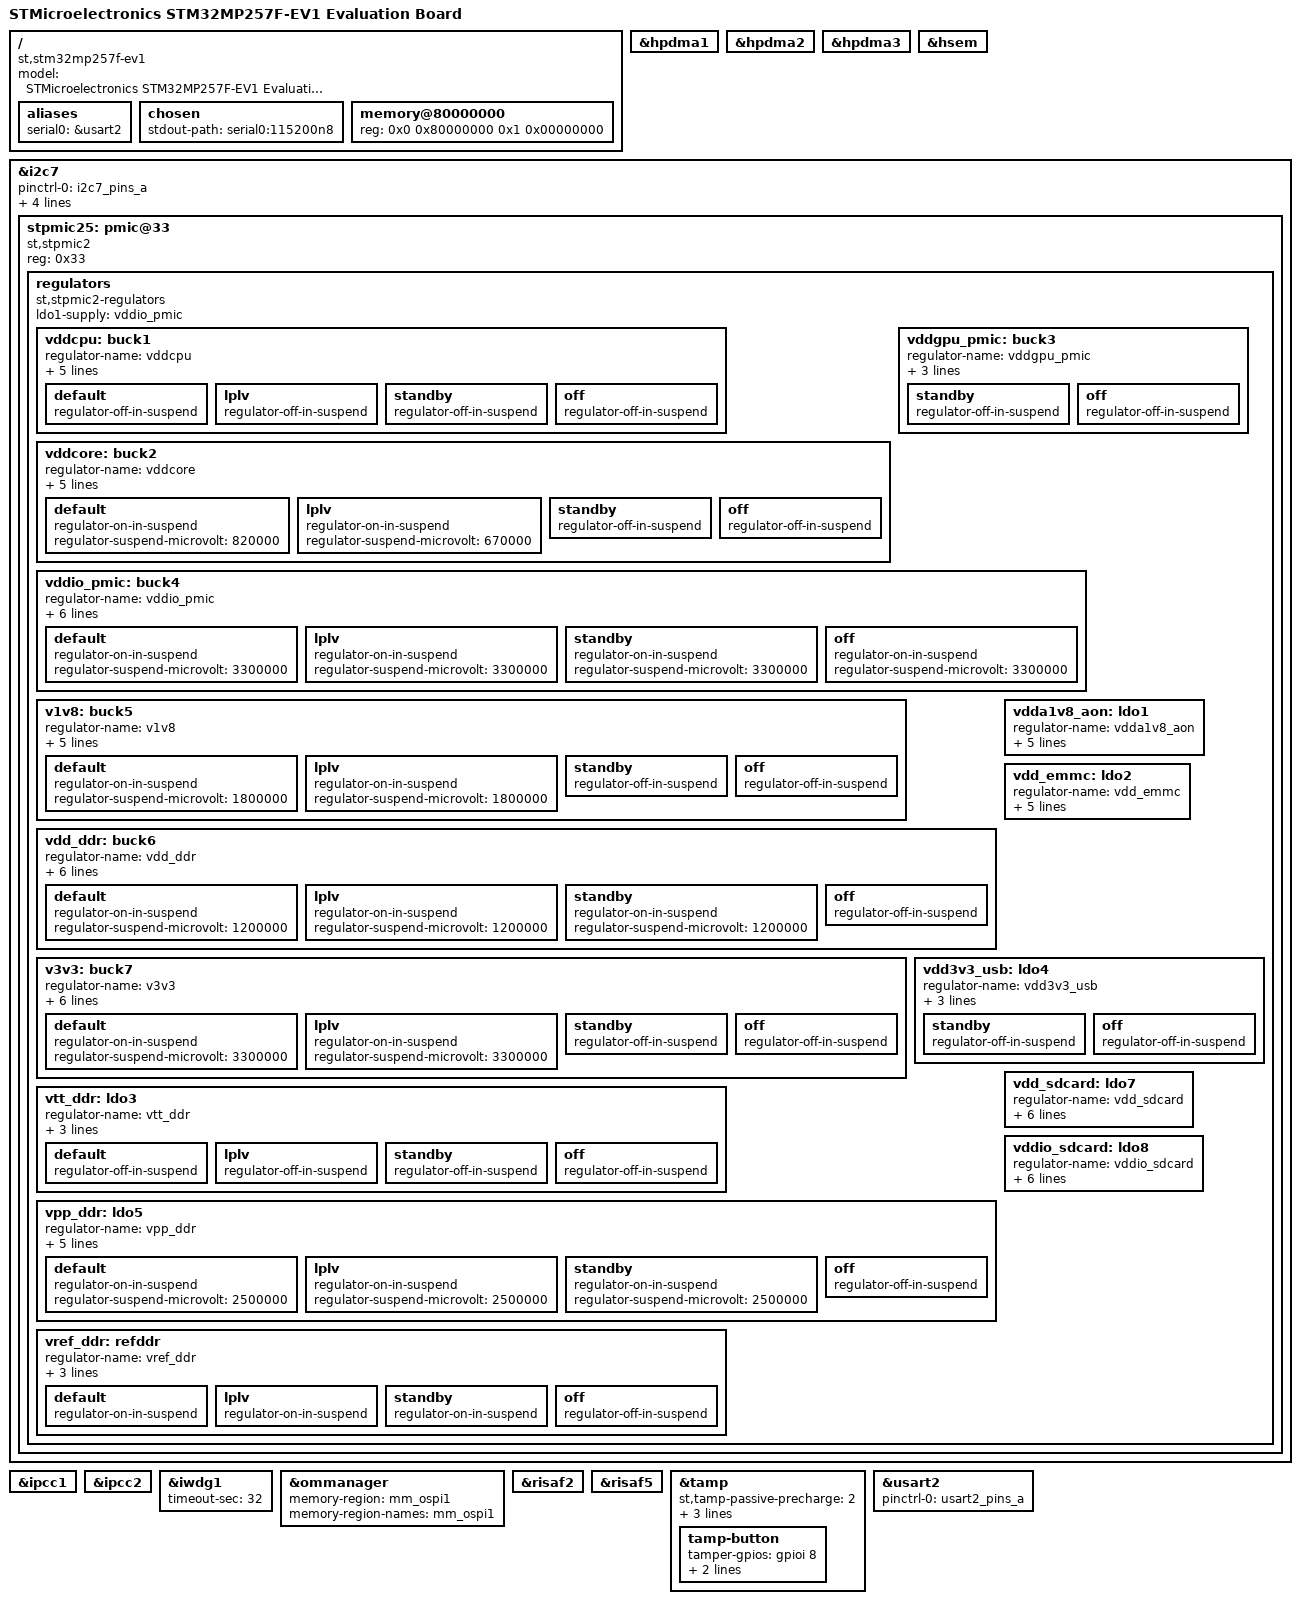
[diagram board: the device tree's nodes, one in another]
// SPDX-License-Identifier: (GPL-2.0-or-later OR BSD-3-Clause)
/*
 * Copyright (C) STMicroelectronics 2023 - All Rights Reserved
 * Author: Alexandre Torgue <alexandre.torgue@foss.st.com> for STMicroelectronics.
 */

/dts-v1/;
#include <dt-bindings/clock/stm32mp25-clksrc.h>
#include <dt-bindings/mfd/st,stpmic2.h>
#include <dt-bindings/tamper/st,stm32mp25-tamp.h>
#include "stm32mp257.dtsi"
#include "stm32mp257f-ev1-ca35tdcid-rcc.dtsi"
#include "stm32mp257f-ev1-ca35tdcid-resmem.dtsi"
#include "stm32mp257f-ev1-ca35tdcid-rif.dtsi"
#include "stm32mp25xf.dtsi"
#include "stm32mp25-pinctrl.dtsi"
#include "stm32mp25-st-scmi-cfg.dtsi"
#include "stm32mp25xxai-pinctrl.dtsi"

/ {
	model = "STMicroelectronics STM32MP257F-EV1 Evaluation Board";
	compatible = "st,stm32mp257f-ev1", "st,stm32mp257";

	aliases {
		serial0 = &usart2;
	};

	chosen {
		stdout-path = "serial0:115200n8";
	};

	memory@80000000 {
		device_type = "memory";
		reg = <0x0 0x80000000 0x1 0x00000000>;
	};
};

&hpdma1 {
	status = "okay";
};

&hpdma2 {
	status = "okay";
};

&hpdma3 {
	status = "okay";
};

&hsem {
	status = "okay";
};

&i2c7 {
	pinctrl-names = "default", "sleep";
	pinctrl-0 = <&i2c7_pins_a>;
	pinctrl-1 = <&i2c7_sleep_pins_a>;
	i2c-scl-rising-time-ns = <29>;
	i2c-scl-falling-time-ns = <7>;
	clock-frequency = <400000>;
	#address-cells = <1>;
	#size-cells = <0>;

	status = "okay";

	stpmic25: pmic@33 {
		compatible = "st,stpmic2";
		reg = <0x33>;

		status = "okay";

		regulators {
			compatible = "st,stpmic2-regulators";
			ldo1-supply = <&vddio_pmic>;

			vddcpu: buck1 {
				regulator-name = "vddcpu";
				regulator-min-microvolt = <800000>;
				regulator-max-microvolt = <910000>;
				regulator-always-on;
				st,pwrctrl-sel = <2>;
				st,pwrctrl-enable;

				default {
					regulator-off-in-suspend;
				};
				lplv {
					regulator-off-in-suspend;
				};
				standby {
					regulator-off-in-suspend;
				};
				off {
					regulator-off-in-suspend;
				};
			};
			vddcore: buck2 {
				regulator-name = "vddcore";
				regulator-min-microvolt = <820000>;
				regulator-max-microvolt = <820000>;
				regulator-always-on;
				st,pwrctrl-sel = <1>;
				st,pwrctrl-enable;

				default {
					regulator-on-in-suspend;
					regulator-suspend-microvolt = <820000>;
				};
				lplv {
					regulator-on-in-suspend;
					regulator-suspend-microvolt = <670000>;
				};
				standby {
					regulator-off-in-suspend;
				};
				off {
					regulator-off-in-suspend;
				};
			};
			vddgpu_pmic: buck3 {
				regulator-name = "vddgpu_pmic";
				regulator-min-microvolt = <800000>;
				regulator-max-microvolt = <900000>;
				regulator-over-current-protection;

				standby {
					regulator-off-in-suspend;
				};
				off {
					regulator-off-in-suspend;
				};
			};
			vddio_pmic: buck4 {
				regulator-name = "vddio_pmic";
				regulator-min-microvolt = <3300000>;
				regulator-max-microvolt = <3300000>;
				regulator-always-on;
				st,mask-reset;
				st,pwrctrl-sel = <1>;
				st,pwrctrl-enable;

				default {
					regulator-on-in-suspend;
					regulator-suspend-microvolt = <3300000>;
				};
				lplv {
					regulator-on-in-suspend;
					regulator-suspend-microvolt = <3300000>;
				};
				standby {
					regulator-on-in-suspend;
					regulator-suspend-microvolt = <3300000>;
				};
				off {
					/* ToDo: switch to LP */
					regulator-on-in-suspend;
					regulator-suspend-microvolt = <3300000>;
				};
			};
			v1v8: buck5 {
				regulator-name = "v1v8";
				regulator-min-microvolt = <1800000>;
				regulator-max-microvolt = <1800000>;
				regulator-always-on;
				st,pwrctrl-sel = <1>;
				st,pwrctrl-enable;

				default {
					regulator-on-in-suspend;
					regulator-suspend-microvolt = <1800000>;
				};
				lplv {
					regulator-on-in-suspend;
					regulator-suspend-microvolt = <1800000>;
				};
				standby {
					regulator-off-in-suspend;
				};
				off {
					regulator-off-in-suspend;
				};
			};
			vdd_ddr: buck6 {
				regulator-name = "vdd_ddr";
				regulator-min-microvolt = <1200000>;
				regulator-max-microvolt = <1200000>;
				regulator-always-on;
				regulator-pull-down;
				st,pwrctrl-sel = <1>;
				st,pwrctrl-enable;

				default {
					regulator-on-in-suspend;
					regulator-suspend-microvolt = <1200000>;
				};
				lplv {
					regulator-on-in-suspend;
					regulator-suspend-microvolt = <1200000>;
				};
				standby {
					regulator-on-in-suspend;
					regulator-suspend-microvolt = <1200000>;
				};
				off {
					regulator-off-in-suspend;
				};
			};
			v3v3: buck7 {
				regulator-name = "v3v3";
				regulator-min-microvolt = <3300000>;
				regulator-max-microvolt = <3300000>;
				regulator-always-on;
				regulator-over-current-protection;
				st,pwrctrl-sel = <1>;
				st,pwrctrl-enable;

				default {
					regulator-on-in-suspend;
					regulator-suspend-microvolt = <3300000>;
				};
				lplv {
					regulator-on-in-suspend;
					regulator-suspend-microvolt = <3300000>;
				};
				standby {
					regulator-off-in-suspend;
				};
				off {
					regulator-off-in-suspend;
				};
			};
			vdda1v8_aon: ldo1 {
				regulator-name = "vdda1v8_aon";
				regulator-min-microvolt = <1800000>;
				regulator-max-microvolt = <1800000>;
				regulator-always-on;
				st,alternate-input-source;
				st,mask-reset;
			};
			vdd_emmc: ldo2 {
				regulator-name = "vdd_emmc";
				regulator-min-microvolt = <3300000>;
				regulator-max-microvolt = <3300000>;
				regulator-over-current-protection;
				st,pwrctrl-sel = <3>;
				st,pwrctrl-reset;
			};
			vtt_ddr: ldo3 {
				regulator-name = "vtt_ddr";
				regulator-always-on;
				st,pwrctrl-sel = <1>;
				st,pwrctrl-enable;

				default {
					regulator-off-in-suspend;
				};
				lplv {
					regulator-off-in-suspend;
				};
				standby {
					regulator-off-in-suspend;
				};
				off {
					regulator-off-in-suspend;
				};
			};
			vdd3v3_usb: ldo4 {
				regulator-name = "vdd3v3_usb";
				regulator-min-microvolt = <3300000>;
				regulator-max-microvolt = <3300000>;
				regulator-over-current-protection;

				standby {
					regulator-off-in-suspend;
				};
				off {
					regulator-off-in-suspend;
				};
			};
			vpp_ddr: ldo5 {
				regulator-name = "vpp_ddr";
				regulator-min-microvolt = <2500000>;
				regulator-max-microvolt = <2500000>;
				regulator-always-on;
				st,pwrctrl-sel = <1>;
				st,pwrctrl-enable;

				default {
					regulator-on-in-suspend;
					regulator-suspend-microvolt = <2500000>;
				};
				lplv {
					regulator-on-in-suspend;
					regulator-suspend-microvolt = <2500000>;
				};
				standby {
					regulator-on-in-suspend;
					regulator-suspend-microvolt = <2500000>;
				};
				off {
					regulator-off-in-suspend;
				};
			};
			vdd_sdcard: ldo7 {
				regulator-name = "vdd_sdcard";
				regulator-min-microvolt = <3300000>;
				regulator-max-microvolt = <3300000>;
				regulator-over-current-protection;
				st,regulator-bypass-microvolt = <3300000>;
				st,pwrctrl-sel = <3>;
				st,pwrctrl-reset;
			};
			vddio_sdcard: ldo8 {
				regulator-name = "vddio_sdcard";
				regulator-min-microvolt = <1800000>;
				regulator-max-microvolt = <3300000>;
				regulator-over-current-protection;
				st,regulator-bypass-microvolt = <3300000>;
				st,pwrctrl-sel = <3>;
				st,pwrctrl-reset;
			};
			vref_ddr: refddr {
				regulator-name = "vref_ddr";
				regulator-always-on;
				st,pwrctrl-sel = <1>;
				st,pwrctrl-enable;

				default {
					regulator-on-in-suspend;
				};
				lplv {
					regulator-on-in-suspend;
				};
				standby {
					regulator-on-in-suspend;
				};
				off {
					regulator-off-in-suspend;
				};
			};
		};
	};
};

&ipcc1 {
	status = "okay";
};

&ipcc2 {
	status = "okay";
};

&iwdg1 {
	timeout-sec = <32>;
	status = "okay";
};

&ommanager {
	memory-region = <&mm_ospi1>;
	memory-region-names = "mm_ospi1";
	status = "okay";
};

&risaf2 {
	status = "okay";
};

&risaf5 {
	status = "okay";
};

&tamp {
	st,tamp-passive-precharge = <2>;
	st,tamp-passive-nb-sample = <4>;
	st,tamp-passive-sample-clk-div = <16384>;
	wakeup-source;

	/* Tamper button */
	tamp-button {
		status = "okay";
		tamper-gpios = <&gpioi 8 0>;
		st,tamp-mode = <TAMPER_CONFIRMED_MODE>;
		st,tamp-id = <1>;
	};
};

&usart2 {
	pinctrl-names = "default";
	pinctrl-0 = <&usart2_pins_a>;
	status = "okay";
};
